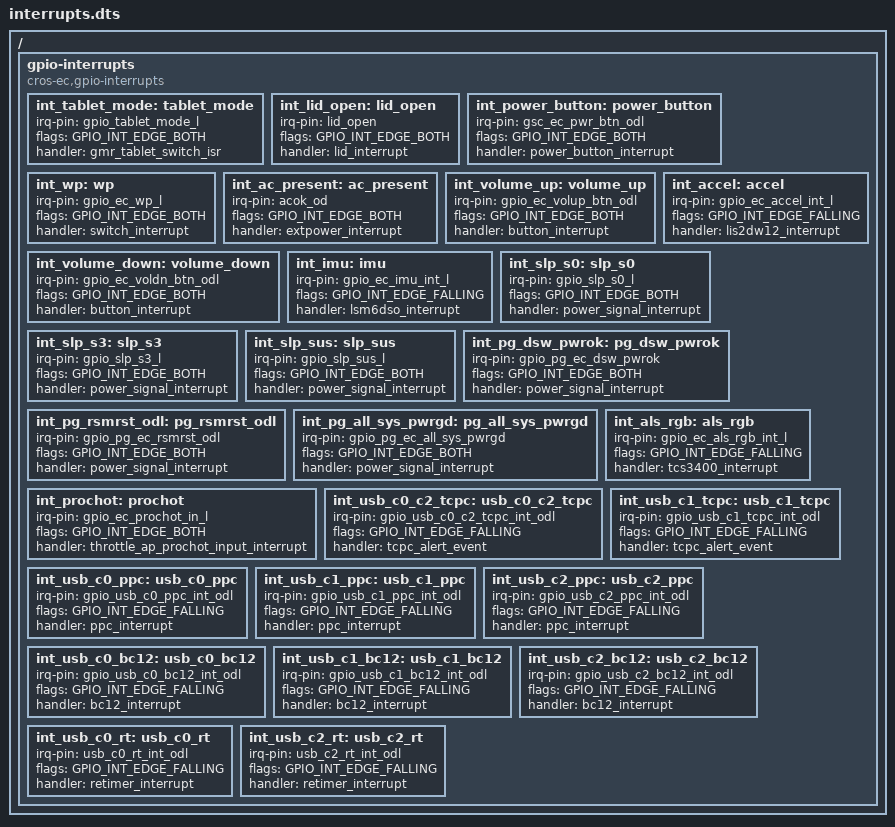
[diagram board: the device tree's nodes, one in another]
/* Copyright 2022 The Chromium OS Authors. All rights reserved.
 * Use of this source code is governed by a BSD-style license that can be
 * found in the LICENSE file.
 */

/ {
	gpio-interrupts {
		compatible = "cros-ec,gpio-interrupts";

		int_tablet_mode: tablet_mode {
			irq-pin = <&gpio_tablet_mode_l>;
			flags = <GPIO_INT_EDGE_BOTH>;
			handler = "gmr_tablet_switch_isr";
		};
		int_lid_open: lid_open {
			irq-pin = <&lid_open>;
			flags = <GPIO_INT_EDGE_BOTH>;
			handler = "lid_interrupt";
		};
		int_power_button: power_button {
			irq-pin = <&gsc_ec_pwr_btn_odl>;
			flags = <GPIO_INT_EDGE_BOTH>;
			handler = "power_button_interrupt";
		};
		int_wp: wp {
			irq-pin = <&gpio_ec_wp_l>;
			flags = <GPIO_INT_EDGE_BOTH>;
			handler = "switch_interrupt";
		};
		int_ac_present: ac_present {
			irq-pin = <&acok_od>;
			flags = <GPIO_INT_EDGE_BOTH>;
			handler = "extpower_interrupt";
		};
		int_volume_up: volume_up {
			irq-pin = <&gpio_ec_volup_btn_odl>;
			flags = <GPIO_INT_EDGE_BOTH>;
			handler = "button_interrupt";
		};
		int_volume_down: volume_down {
			irq-pin = <&gpio_ec_voldn_btn_odl>;
			flags = <GPIO_INT_EDGE_BOTH>;
			handler = "button_interrupt";
		};
		int_accel: accel {
			irq-pin = <&gpio_ec_accel_int_l>;
			flags = <GPIO_INT_EDGE_FALLING>;
			handler = "lis2dw12_interrupt";
		};
		int_imu: imu {
			irq-pin = <&gpio_ec_imu_int_l>;
			flags = <GPIO_INT_EDGE_FALLING>;
			handler = "lsm6dso_interrupt";
		};
		int_slp_s0: slp_s0 {
			irq-pin = <&gpio_slp_s0_l>;
			flags = <GPIO_INT_EDGE_BOTH>;
			handler = "power_signal_interrupt";
		};
		int_slp_s3: slp_s3 {
			irq-pin = <&gpio_slp_s3_l>;
			flags = <GPIO_INT_EDGE_BOTH>;
			handler = "power_signal_interrupt";
		};
		int_slp_sus: slp_sus {
			irq-pin = <&gpio_slp_sus_l>;
			flags = <GPIO_INT_EDGE_BOTH>;
			handler = "power_signal_interrupt";
		};
		int_pg_dsw_pwrok: pg_dsw_pwrok {
			irq-pin = <&gpio_pg_ec_dsw_pwrok>;
			flags = <GPIO_INT_EDGE_BOTH>;
			handler = "power_signal_interrupt";
		};
		int_pg_rsmrst_odl: pg_rsmrst_odl {
			irq-pin = <&gpio_pg_ec_rsmrst_odl>;
			flags = <GPIO_INT_EDGE_BOTH>;
			handler = "power_signal_interrupt";
		};
		int_pg_all_sys_pwrgd: pg_all_sys_pwrgd {
			irq-pin = <&gpio_pg_ec_all_sys_pwrgd>;
			flags = <GPIO_INT_EDGE_BOTH>;
			handler = "power_signal_interrupt";
		};
		int_als_rgb: als_rgb {
			irq-pin = <&gpio_ec_als_rgb_int_l>;
			flags = <GPIO_INT_EDGE_FALLING>;
			handler = "tcs3400_interrupt";
		};
		int_prochot: prochot {
			irq-pin = <&gpio_ec_prochot_in_l>;
			flags = <GPIO_INT_EDGE_BOTH>;
			handler = "throttle_ap_prochot_input_interrupt";
		};
		int_usb_c0_c2_tcpc: usb_c0_c2_tcpc {
			irq-pin = <&gpio_usb_c0_c2_tcpc_int_odl>;
			flags = <GPIO_INT_EDGE_FALLING>;
			handler = "tcpc_alert_event";
		};
		int_usb_c1_tcpc: usb_c1_tcpc {
			irq-pin = <&gpio_usb_c1_tcpc_int_odl>;
			flags = <GPIO_INT_EDGE_FALLING>;
			handler = "tcpc_alert_event";
		};
		int_usb_c0_ppc: usb_c0_ppc {
			irq-pin = <&gpio_usb_c0_ppc_int_odl>;
			flags = <GPIO_INT_EDGE_FALLING>;
			handler = "ppc_interrupt";
		};
		int_usb_c1_ppc: usb_c1_ppc {
			irq-pin = <&gpio_usb_c1_ppc_int_odl>;
			flags = <GPIO_INT_EDGE_FALLING>;
			handler = "ppc_interrupt";
		};
		int_usb_c2_ppc: usb_c2_ppc {
			irq-pin = <&gpio_usb_c2_ppc_int_odl>;
			flags = <GPIO_INT_EDGE_FALLING>;
			handler = "ppc_interrupt";
		};
		int_usb_c0_bc12: usb_c0_bc12 {
			irq-pin = <&gpio_usb_c0_bc12_int_odl>;
			flags = <GPIO_INT_EDGE_FALLING>;
			handler = "bc12_interrupt";
		};
		int_usb_c1_bc12: usb_c1_bc12 {
			irq-pin = <&gpio_usb_c1_bc12_int_odl>;
			flags = <GPIO_INT_EDGE_FALLING>;
			handler = "bc12_interrupt";
		};
		int_usb_c2_bc12: usb_c2_bc12 {
			irq-pin = <&gpio_usb_c2_bc12_int_odl>;
			flags = <GPIO_INT_EDGE_FALLING>;
			handler = "bc12_interrupt";
		};
		int_usb_c0_rt: usb_c0_rt {
			irq-pin = <&usb_c0_rt_int_odl>;
			flags = <GPIO_INT_EDGE_FALLING>;
			handler = "retimer_interrupt";
		};
		int_usb_c2_rt: usb_c2_rt {
			irq-pin = <&usb_c2_rt_int_odl>;
			flags = <GPIO_INT_EDGE_FALLING>;
			handler = "retimer_interrupt";
		};
	};
};
